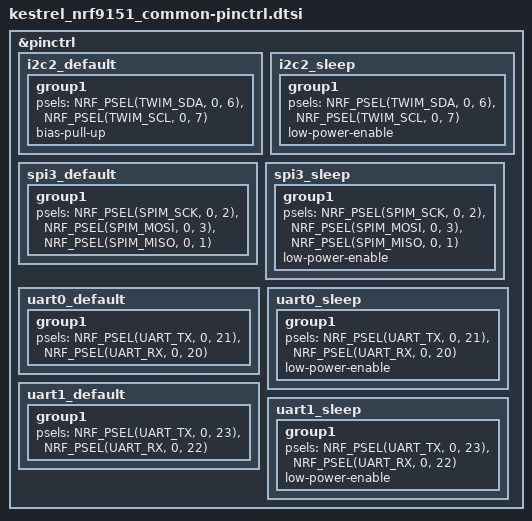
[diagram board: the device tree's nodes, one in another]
/*
 * Copyright (c) 2024 Nordic Semiconductor
 * SPDX-License-Identifier: LicenseRef-Nordic-5-Clause
 */

&pinctrl {
	/* PWM0 pinctrl removed - RGB LEDs not present on standalone design */

	i2c2_default: i2c2_default {
		group1 {
			psels = <NRF_PSEL(TWIM_SDA, 0, 6)>,
				<NRF_PSEL(TWIM_SCL, 0, 7)>;
				bias-pull-up;
		};
	};

	i2c2_sleep: i2c2_sleep {
		group1 {
			psels = <NRF_PSEL(TWIM_SDA, 0, 6)>,
				<NRF_PSEL(TWIM_SCL, 0, 7)>;
			low-power-enable;
		};
	};

	spi3_default: spi3_default {
		group1 {
			psels = <NRF_PSEL(SPIM_SCK, 0, 2)>,
				<NRF_PSEL(SPIM_MOSI, 0, 3)>,
				<NRF_PSEL(SPIM_MISO, 0, 1)>;
		};
	};

	spi3_sleep: spi3_sleep {
		group1 {
			psels = <NRF_PSEL(SPIM_SCK, 0, 2)>,
				<NRF_PSEL(SPIM_MOSI, 0, 3)>,
				<NRF_PSEL(SPIM_MISO, 0, 1)>;
			low-power-enable;
		};
	};

	uart0_default: uart0_default {
		group1 {
			psels = <NRF_PSEL(UART_TX, 0, 21)>,
				<NRF_PSEL(UART_RX, 0, 20)>;
		};
	};

	uart0_sleep: uart0_sleep {
		group1 {
			psels = <NRF_PSEL(UART_TX, 0, 21)>,
				<NRF_PSEL(UART_RX, 0, 20)>;
			low-power-enable;
		};
	};

	uart1_default: uart1_default {
		group1 {
			psels = <NRF_PSEL(UART_TX, 0, 23)>,
				<NRF_PSEL(UART_RX, 0, 22)>;
		};
	};

	uart1_sleep: uart1_sleep {
		group1 {
			psels = <NRF_PSEL(UART_TX, 0, 23)>,
				<NRF_PSEL(UART_RX, 0, 22)>;
			low-power-enable;
		};
	};

	//New version of the board does not have i2c1 connected to any external components

	// i2c1_default: i2c1_default {
	// 	group1 {
	// 		psels = <NRF_PSEL(TWIM_SDA, 0, 8)>,
	// 			<NRF_PSEL(TWIM_SCL, 0, 9)>;
	// 	};
	// };

	// i2c1_sleep: i2c1_sleep {
	// 	group1 {
	// 		psels = <NRF_PSEL(TWIM_SDA, 0, 8)>,
	// 			<NRF_PSEL(TWIM_SCL, 0, 9)>;
	// 		low-power-enable;
	// 	};
	// };



};
